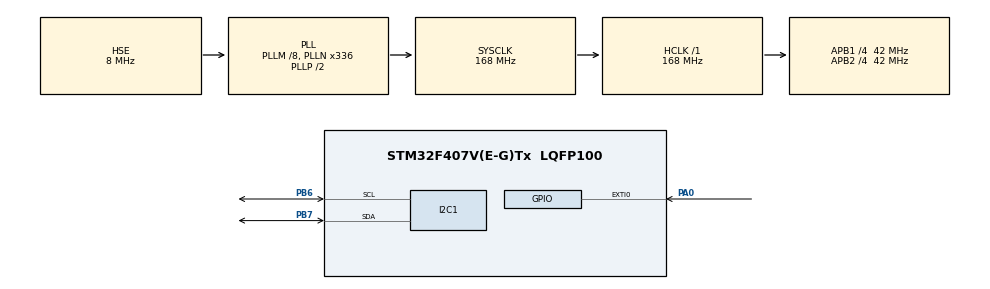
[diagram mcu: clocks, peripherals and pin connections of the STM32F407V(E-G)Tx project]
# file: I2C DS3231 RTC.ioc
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Dma.I2C1_RX.0.Direction=DMA_PERIPH_TO_MEMORY
Dma.I2C1_RX.0.FIFOMode=DMA_FIFOMODE_DISABLE
Dma.I2C1_RX.0.Instance=DMA1_Stream0
Dma.I2C1_RX.0.MemDataAlignment=DMA_MDATAALIGN_BYTE
Dma.I2C1_RX.0.MemInc=DMA_MINC_ENABLE
Dma.I2C1_RX.0.Mode=DMA_CIRCULAR
Dma.I2C1_RX.0.PeriphDataAlignment=DMA_PDATAALIGN_BYTE
Dma.I2C1_RX.0.PeriphInc=DMA_PINC_DISABLE
Dma.I2C1_RX.0.Priority=DMA_PRIORITY_LOW
Dma.Request0=I2C1_RX
I2C1.I2C_Mode=I2C_Fast
Mcu.Family=STM32F4
Mcu.Name=STM32F407V(E-G)Tx
Mcu.Package=LQFP100
NVIC.DMA1_Stream0_IRQn=true\:0\:0\:false\:false\:true\:true
NVIC.EXTI0_IRQn=true\:0\:0\:false\:false\:true\:true
NVIC.I2C1_EV_IRQn=true\:0\:0\:false\:false\:true\:true
NVIC.PriorityGroup=NVIC_PRIORITYGROUP_4
PA0-WKUP.GPIO_ModeDefaultEXTI=GPIO_MODE_IT_RISING
PA0-WKUP.GPIO_PuPd=GPIO_NOPULL
PA0-WKUP.Signal=GPXTI0
PB6.Mode=I2C
PB6.Signal=I2C1_SCL
PB7.Mode=I2C
PB7.Signal=I2C1_SDA
PH0-OSC_IN.Mode=HSE-External-Oscillator
PH0-OSC_IN.Signal=RCC_OSC_IN
PH1-OSC_OUT.Mode=HSE-External-Oscillator
PH1-OSC_OUT.Signal=RCC_OSC_OUT
ProjectManager.HeapSize=0x200
ProjectManager.StackSize=0x400
ProjectManager.TargetToolchain=MDK-ARM V5
RCC.48MHZClocksFreq_Value=84000000
RCC.AHBFreq_Value=168000000
RCC.APB1CLKDivider=RCC_HCLK_DIV4
RCC.APB1Freq_Value=42000000
RCC.APB1TimFreq_Value=84000000
RCC.APB2CLKDivider=RCC_HCLK_DIV4
RCC.APB2Freq_Value=42000000
RCC.APB2TimFreq_Value=84000000
RCC.CortexFreq_Value=168000000
RCC.HCLKFreq_Value=168000000
RCC.HSE_VALUE=8000000
RCC.HSI_VALUE=16000000
RCC.LSE_VALUE=32768
RCC.PLLM=8
RCC.PLLN=336
RCC.PLLSourceVirtual=RCC_PLLSOURCE_HSE
RCC.SYSCLKFreq_VALUE=168000000
RCC.SYSCLKSource=RCC_SYSCLKSOURCE_PLLCLK
RCC.VCOOutputFreq_Value=336000000
board=I2C DS3231 RTC

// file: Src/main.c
/**
  ******************************************************************************
  * @file           : main.c
  * @brief          : Main program body
  ******************************************************************************
  ** This notice applies to any and all portions of this file
  * that are not between comment pairs USER CODE BEGIN and
  * USER CODE END. Other portions of this file, whether
  * inserted by the user or by software development tools
  * are owned by their respective copyright owners.
  *
  * COPYRIGHT(c) 2018 STMicroelectronics
  *
  * Redistribution and use in source and binary forms, with or without modification,
  * are permitted provided that the following conditions are met:
  *   1. Redistributions of source code must retain the above copyright notice,
  *      this list of conditions and the following disclaimer.
  *   2. Redistributions in binary form must reproduce the above copyright notice,
  *      this list of conditions and the following disclaimer in the documentation
  *      and/or other materials provided with the distribution.
  *   3. Neither the name of STMicroelectronics nor the names of its contributors
  *      may be used to endorse or promote products derived from this software
  *      without specific prior written permission.
  *
  * THIS SOFTWARE IS PROVIDED BY THE COPYRIGHT HOLDERS AND CONTRIBUTORS "AS IS"
  * AND ANY EXPRESS OR IMPLIED WARRANTIES, INCLUDING, BUT NOT LIMITED TO, THE
  * IMPLIED WARRANTIES OF MERCHANTABILITY AND FITNESS FOR A PARTICULAR PURPOSE ARE
  * DISCLAIMED. IN NO EVENT SHALL THE COPYRIGHT HOLDER OR CONTRIBUTORS BE LIABLE
  * FOR ANY DIRECT, INDIRECT, INCIDENTAL, SPECIAL, EXEMPLARY, OR CONSEQUENTIAL
  * DAMAGES (INCLUDING, BUT NOT LIMITED TO, PROCUREMENT OF SUBSTITUTE GOODS OR
  * SERVICES; LOSS OF USE, DATA, OR PROFITS; OR BUSINESS INTERRUPTION) HOWEVER
  * CAUSED AND ON ANY THEORY OF LIABILITY, WHETHER IN CONTRACT, STRICT LIABILITY,
  * OR TORT (INCLUDING NEGLIGENCE OR OTHERWISE) ARISING IN ANY WAY OUT OF THE USE
  * OF THIS SOFTWARE, EVEN IF ADVISED OF THE POSSIBILITY OF SUCH DAMAGE.
  *
  ******************************************************************************
  */
#include "main.h"
#include "stm32f4xx_hal.h"

/* USER CODE BEGIN Includes */
#define DS3231_ADD 0x68
uint8_t BCD2DEC(uint8_t data);
uint8_t DEC2BCD(uint8_t data);
/* USER CODE END Includes */

I2C_HandleTypeDef hi2c1;
DMA_HandleTypeDef hdma_i2c1_rx;

/* USER CODE BEGIN PV */
/* Private variables ---------------------------------------------------------*/

/* USER CODE END PV */

void SystemClock_Config(void);
static void MX_GPIO_Init(void);
static void MX_DMA_Init(void);
static void MX_I2C1_Init(void);

/* USER CODE BEGIN PFP */
/* Private function prototypes -----------------------------------------------*/
uint8_t receive_data[7], send_data[7];
uint8_t second, minute, hour, day, date, month, year;
/* USER CODE END PFP */

int main(void)
{

  /* MCU Configuration----------------------------------------------------------*/

  /* Reset of all peripherals, Initializes the Flash interface and the Systick. */
  HAL_Init();

  /* Configure the system clock */
  SystemClock_Config();

  /* Initialize all configured peripherals */
  MX_GPIO_Init();
  MX_DMA_Init();
  MX_I2C1_Init();

  /* Infinite loop */
  /* USER CODE BEGIN WHILE */
  while (1)
  {
    HAL_I2C_Mem_Read_DMA(&hi2c1, DS3231_ADD << 1, 0, I2C_MEMADD_SIZE_8BIT, receive_data, 7);
    HAL_Delay(200);
    /* USER CODE END WHILE */

  }
}

void SystemClock_Config(void)
{

  RCC_OscInitTypeDef RCC_OscInitStruct;
  RCC_ClkInitTypeDef RCC_ClkInitStruct;

  /**Configure the main internal regulator output voltage
    */
  __HAL_RCC_PWR_CLK_ENABLE();

  __HAL_PWR_VOLTAGESCALING_CONFIG(PWR_REGULATOR_VOLTAGE_SCALE1);

  /**Initializes the CPU, AHB and APB busses clocks
    */
  RCC_OscInitStruct.OscillatorType = RCC_OSCILLATORTYPE_HSE;
  RCC_OscInitStruct.HSEState = RCC_HSE_ON;
  RCC_OscInitStruct.PLL.PLLState = RCC_PLL_ON;
  RCC_OscInitStruct.PLL.PLLSource = RCC_PLLSOURCE_HSE;
  RCC_OscInitStruct.PLL.PLLM = 8;
  RCC_OscInitStruct.PLL.PLLN = 336;
  RCC_OscInitStruct.PLL.PLLP = RCC_PLLP_DIV2;
  RCC_OscInitStruct.PLL.PLLQ = 4;
  if (HAL_RCC_OscConfig(&RCC_OscInitStruct) != HAL_OK)
  {
    _Error_Handler(__FILE__, __LINE__);
  }

  /**Initializes the CPU, AHB and APB busses clocks
    */
  RCC_ClkInitStruct.ClockType = RCC_CLOCKTYPE_HCLK | RCC_CLOCKTYPE_SYSCLK | RCC_CLOCKTYPE_PCLK1 | RCC_CLOCKTYPE_PCLK2;
  RCC_ClkInitStruct.SYSCLKSource = RCC_SYSCLKSOURCE_PLLCLK;
  RCC_ClkInitStruct.AHBCLKDivider = RCC_SYSCLK_DIV1;
  RCC_ClkInitStruct.APB1CLKDivider = RCC_HCLK_DIV4;
  RCC_ClkInitStruct.APB2CLKDivider = RCC_HCLK_DIV4;

  if (HAL_RCC_ClockConfig(&RCC_ClkInitStruct, FLASH_LATENCY_5) != HAL_OK)
  {
    _Error_Handler(__FILE__, __LINE__);
  }

  /**Configure the Systick interrupt time
    */
  HAL_SYSTICK_Config(HAL_RCC_GetHCLKFreq() / 1000);

  /**Configure the Systick
    */
  HAL_SYSTICK_CLKSourceConfig(SYSTICK_CLKSOURCE_HCLK);

  /* SysTick_IRQn interrupt configuration */
  HAL_NVIC_SetPriority(SysTick_IRQn, 0, 0);
}

/* I2C1 init function */
static void MX_I2C1_Init(void)
{

  hi2c1.Instance = I2C1;
  hi2c1.Init.ClockSpeed = 400000;
  hi2c1.Init.DutyCycle = I2C_DUTYCYCLE_2;
  hi2c1.Init.OwnAddress1 = 0;
  hi2c1.Init.AddressingMode = I2C_ADDRESSINGMODE_7BIT;
  hi2c1.Init.DualAddressMode = I2C_DUALADDRESS_DISABLE;
  hi2c1.Init.OwnAddress2 = 0;
  hi2c1.Init.GeneralCallMode = I2C_GENERALCALL_DISABLE;
  hi2c1.Init.NoStretchMode = I2C_NOSTRETCH_DISABLE;
  if (HAL_I2C_Init(&hi2c1) != HAL_OK)
  {
    _Error_Handler(__FILE__, __LINE__);
  }
}

static void MX_DMA_Init(void)
{
  /* DMA controller clock enable */
  __HAL_RCC_DMA1_CLK_ENABLE();

  /* DMA interrupt init */
  /* DMA1_Stream0_IRQn interrupt configuration */
  HAL_NVIC_SetPriority(DMA1_Stream0_IRQn, 0, 0);
  HAL_NVIC_EnableIRQ(DMA1_Stream0_IRQn);
}

/** Configure pins as
        * Analog
        * Input
        * Output
        * EVENT_OUT
        * EXTI
*/
static void MX_GPIO_Init(void)
{

  GPIO_InitTypeDef GPIO_InitStruct;

  /* GPIO Ports Clock Enable */
  __HAL_RCC_GPIOH_CLK_ENABLE();
  __HAL_RCC_GPIOA_CLK_ENABLE();
  __HAL_RCC_GPIOB_CLK_ENABLE();

  /*Configure GPIO pin : PA0 */
  GPIO_InitStruct.Pin = GPIO_PIN_0;
  GPIO_InitStruct.Mode = GPIO_MODE_IT_RISING;
  GPIO_InitStruct.Pull = GPIO_NOPULL;
  HAL_GPIO_Init(GPIOA, &GPIO_InitStruct);

  /* EXTI interrupt init*/
  HAL_NVIC_SetPriority(EXTI0_IRQn, 0, 0);
  HAL_NVIC_EnableIRQ(EXTI0_IRQn);
}

/* USER CODE BEGIN 4 */
void HAL_GPIO_EXTI_Callback(uint16_t GPIO_Pin)
{
  if (GPIO_Pin == GPIO_PIN_0)
  {
    // 12h:12m:12s Monday 12/12/12
    send_data[0] = DEC2BCD(12);
    send_data[1] = DEC2BCD(12);
    send_data[2] = DEC2BCD(12);

    send_data[3] = DEC2BCD(2);
    send_data[4] = DEC2BCD(12);
    send_data[5] = DEC2BCD(12);
    send_data[6] = DEC2BCD(12);
    HAL_I2C_Mem_Write_IT(&hi2c1, DS3231_ADD << 1, 0, I2C_MEMADD_SIZE_8BIT, send_data, 7);
  }
}

void HAL_I2C_MemRxCpltCallback(I2C_HandleTypeDef *hi2c)
{
  if (hi2c->Instance == hi2c1.Instance)
  {
    second = BCD2DEC(receive_data[0]);
    minute = BCD2DEC(receive_data[1]);
    hour = BCD2DEC(receive_data[2]);

    day = BCD2DEC(receive_data[3]);
    date = BCD2DEC(receive_data[4]);
    month = BCD2DEC(receive_data[5]);
    year = BCD2DEC(receive_data[6]);
  }
}

uint8_t BCD2DEC(uint8_t data)
{
  return (data >> 4) * 10 + (data & 0x0f);
}

uint8_t DEC2BCD(uint8_t data)
{
  return (data / 10) << 4 | (data % 10);
}
/* USER CODE END 4 */

void _Error_Handler(char *file, int line)
{
  while (1)
  {
  }
}

/************************ (C) COPYRIGHT STMicroelectronics *****END OF FILE****/
